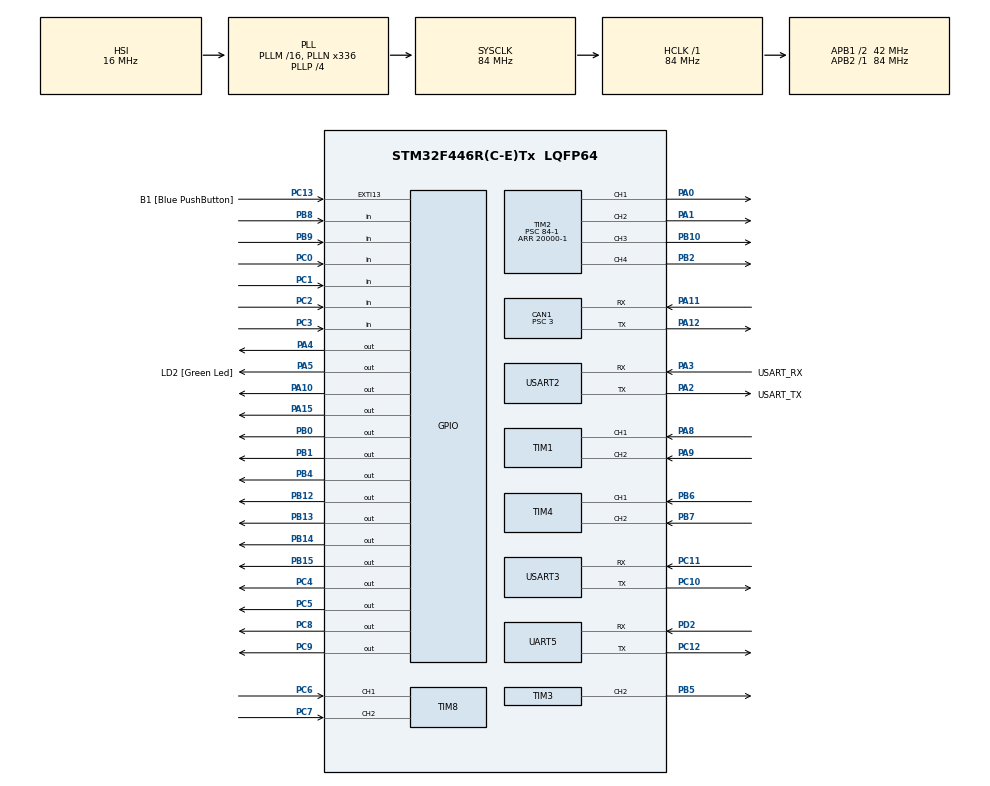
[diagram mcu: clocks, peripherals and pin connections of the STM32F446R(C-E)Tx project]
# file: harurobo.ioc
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CAN1.BS1=CAN_BS1_12TQ
CAN1.CalculateBaudRate=1000000
CAN1.CalculateTimeBit=1000
CAN1.CalculateTimeQuantum=71.42857142857143
CAN1.NART=DISABLE
CAN1.Prescaler=3
CAN1.SJW=CAN_SJW_1TQ
Dma.Request0=TIM3_CH2
Dma.TIM3_CH2.0.Direction=DMA_MEMORY_TO_PERIPH
Dma.TIM3_CH2.0.FIFOMode=DMA_FIFOMODE_DISABLE
Dma.TIM3_CH2.0.Instance=DMA1_Stream5
Dma.TIM3_CH2.0.MemDataAlignment=DMA_MDATAALIGN_WORD
Dma.TIM3_CH2.0.MemInc=DMA_MINC_ENABLE
Dma.TIM3_CH2.0.Mode=DMA_CIRCULAR
Dma.TIM3_CH2.0.PeriphDataAlignment=DMA_PDATAALIGN_WORD
Dma.TIM3_CH2.0.PeriphInc=DMA_PINC_DISABLE
Dma.TIM3_CH2.0.Priority=DMA_PRIORITY_VERY_HIGH
Mcu.Family=STM32F4
Mcu.Name=STM32F446R(C-E)Tx
Mcu.Package=LQFP64
NVIC.CAN1_RX0_IRQn=true\:1\:0\:true\:false\:true\:true\:true\:true
NVIC.DMA1_Stream5_IRQn=true\:0\:0\:false\:false\:true\:false\:true\:true
NVIC.PriorityGroup=NVIC_PRIORITYGROUP_4
NVIC.TIM5_IRQn=true\:3\:0\:true\:false\:true\:true\:true\:true
NVIC.TIM6_DAC_IRQn=true\:2\:0\:true\:false\:true\:true\:true\:true
NVIC.TIM7_IRQn=true\:2\:0\:true\:false\:true\:true\:true\:true
NVIC.UART5_IRQn=true\:1\:0\:true\:false\:true\:true\:true\:true
NVIC.USART2_IRQn=true\:1\:0\:true\:false\:true\:true\:true\:true
NVIC.USART3_IRQn=true\:1\:0\:true\:false\:true\:true\:true\:true
PA0-WKUP.Signal=S_TIM2_CH1_ETR
PA1.Signal=S_TIM2_CH2
PA10.Signal=GPIO_Output
PA11.Mode=CAN_Activate
PA11.Signal=CAN1_RX
PA12.Mode=CAN_Activate
PA12.Signal=CAN1_TX
PA13.GPIO_Label=TMS
PA13.Mode=Serial_Wire
PA13.Signal=SYS_JTMS-SWDIO
PA14.GPIO_Label=TCK
PA14.Mode=Serial_Wire
PA14.Signal=SYS_JTCK-SWCLK
PA15.Signal=GPIO_Output
PA2.GPIO_Label=USART_TX
PA2.Mode=Asynchronous
PA2.Signal=USART2_TX
PA3.GPIO_Label=USART_RX
PA3.Mode=Asynchronous
PA3.Signal=USART2_RX
PA4.Signal=GPIO_Output
PA5.GPIO_Label=LD2 [Green Led]
PA5.Signal=GPIO_Output
PA6.Signal=S_TIM3_CH1
PA8.Signal=S_TIM1_CH1
PA9.Signal=S_TIM1_CH2
PB0.Signal=GPIO_Output
PB1.Signal=GPIO_Output
PB10.Signal=S_TIM2_CH3
PB12.Signal=GPIO_Output
PB13.Signal=GPIO_Output
PB14.Signal=GPIO_Output
PB15.Signal=GPIO_Output
PB2.Signal=S_TIM2_CH4
PB3.GPIO_Label=SWO
PB3.Signal=SYS_JTDO-SWO
PB4.Signal=GPIO_Output
PB5.Signal=S_TIM3_CH2
PB6.Signal=S_TIM4_CH1
PB7.Signal=S_TIM4_CH2
PB8.Signal=GPIO_Input
PB9.Signal=GPIO_Input
PC0.Signal=GPIO_Input
PC1.Signal=GPIO_Input
PC10.Mode=Asynchronous
PC10.Signal=USART3_TX
PC11.Mode=Asynchronous
PC11.Signal=USART3_RX
PC12.Mode=Asynchronous
PC12.Signal=UART5_TX
PC13.GPIO_Label=B1 [Blue PushButton]
PC13.GPIO_ModeDefaultEXTI=GPIO_MODE_IT_FALLING
PC13.Signal=GPXTI13
PC14-OSC32_IN.Mode=LSE-External-Oscillator
PC14-OSC32_IN.Signal=RCC_OSC32_IN
PC15-OSC32_OUT.Mode=LSE-External-Oscillator
PC15-OSC32_OUT.Signal=RCC_OSC32_OUT
PC2.Signal=GPIO_Input
PC3.Signal=GPIO_Input
PC4.Signal=GPIO_Output
PC5.Signal=GPIO_Output
PC6.Signal=S_TIM8_CH1
PC7.Signal=S_TIM8_CH2
PC8.Signal=GPIO_Output
PC9.Signal=GPIO_Output
PD2.Mode=Asynchronous
PD2.Signal=UART5_RX
PH0-OSC_IN.Mode=HSE-External-Oscillator
PH0-OSC_IN.Signal=RCC_OSC_IN
PH1-OSC_OUT.Mode=HSE-External-Oscillator
PH1-OSC_OUT.Signal=RCC_OSC_OUT
ProjectManager.HeapSize=0x200
ProjectManager.StackSize=0x400
ProjectManager.TargetToolchain=CMake
RCC.48MHZClocksFreq_Value=84000000
RCC.AHBFreq_Value=84000000
RCC.APB1CLKDivider=RCC_HCLK_DIV2
RCC.APB1Freq_Value=42000000
RCC.APB1TimFreq_Value=84000000
RCC.APB2Freq_Value=84000000
RCC.APB2TimFreq_Value=84000000
RCC.CortexFreq_Value=84000000
RCC.FLatency-AdvancedSettings=FLASH_LATENCY_2
RCC.HCLKFreq_Value=84000000
RCC.HSE_VALUE=8000000
RCC.HSI_VALUE=16000000
RCC.PLLN=336
RCC.PLLP=RCC_PLLP_DIV4
RCC.SYSCLKFreq_VALUE=84000000
RCC.SYSCLKSource=RCC_SYSCLKSOURCE_PLLCLK
RCC.USBFreq_Value=168000000
RCC.VCOOutputFreq_Value=336000000
SH.S_TIM1_CH1.0=TIM1_CH1,Encoder_Interface
SH.S_TIM1_CH2.0=TIM1_CH2,Encoder_Interface
SH.S_TIM2_CH1_ETR.0=TIM2_CH1,PWM Generation1 CH1
SH.S_TIM2_CH2.0=TIM2_CH2,PWM Generation2 CH2
SH.S_TIM2_CH3.0=TIM2_CH3,PWM Generation3 CH3
SH.S_TIM2_CH4.0=TIM2_CH4,PWM Generation4 CH4
SH.S_TIM3_CH1.0=TIM3_CH1
SH.S_TIM3_CH2.0=TIM3_CH2,PWM Generation2 CH2
SH.S_TIM4_CH1.0=TIM4_CH1,Encoder_Interface
SH.S_TIM4_CH2.0=TIM4_CH2,Encoder_Interface
SH.S_TIM8_CH1.0=TIM8_CH1,Encoder_Interface
SH.S_TIM8_CH2.0=TIM8_CH2,Encoder_Interface
TIM2.Channel-PWM\ Generation1\ CH1=TIM_CHANNEL_1
TIM2.Channel-PWM\ Generation2\ CH2=TIM_CHANNEL_2
TIM2.Channel-PWM\ Generation3\ CH3=TIM_CHANNEL_3
TIM2.Channel-PWM\ Generation4\ CH4=TIM_CHANNEL_4
TIM2.Period=20000-1
TIM2.Prescaler=84-1
TIM3.Channel-PWM\ Generation2\ CH2=TIM_CHANNEL_2
TIM3.Period=15-1
TIM3.Prescaler=7-1
TIM5.Period=8400-1
TIM5.Prescaler=500-1
TIM6.Period=8400-1
TIM6.Prescaler=100-1
TIM7.Period=8400-1
TIM7.Prescaler=10-1
UART5.VirtualMode=Asynchronous
USART2.VirtualMode=VM_ASYNC
USART3.VirtualMode=VM_ASYNC
VP_TIM12_VS_ClockSourceINT.Mode=Internal
VP_TIM13_VS_ClockSourceINT.Mode=Enable_Timer
VP_TIM3_VS_ClockSourceINT.Mode=Internal
VP_TIM5_VS_ClockSourceINT.Mode=Internal
VP_TIM6_VS_ClockSourceINT.Mode=Enable_Timer
VP_TIM7_VS_ClockSourceINT.Mode=Enable_Timer
board=NUCLEO-F446RE

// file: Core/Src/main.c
/* USER CODE BEGIN Header */
/**
  ******************************************************************************
  * @file           : main.c
  * @brief          : Main program body
  ******************************************************************************
  * @attention
  *
  * Copyright (c) 2024 STMicroelectronics.
  * All rights reserved.
  *
  * This software is licensed under terms that can be found in the LICENSE file
  * in the root directory of this software component.
  * If no LICENSE file comes with this software, it is provided AS-IS.
  *
  ******************************************************************************
  */
/* USER CODE END Header */
#include "main.h"
#include "can.h"
#include "dma.h"
#include "tim.h"
#include "usart.h"
#include "gpio.h"

/* USER CODE BEGIN Includes */
#include "main.hpp"
/* USER CODE END Includes */

void SystemClock_Config(void);

int main(void)
{

  /* MCU Configuration--------------------------------------------------------*/

  /* Reset of all peripherals, Initializes the Flash interface and the Systick. */
  HAL_Init();

  /* Configure the system clock */
  SystemClock_Config();

  /* Initialize all configured peripherals */
  MX_GPIO_Init();
  MX_DMA_Init();
  MX_USART2_UART_Init();
  MX_TIM1_Init();
  MX_TIM2_Init();
  MX_TIM3_Init();
  MX_TIM4_Init();
  MX_TIM6_Init();
  MX_TIM7_Init();
  MX_TIM8_Init();
  MX_TIM12_Init();
  MX_TIM13_Init();
  MX_USART3_UART_Init();
  MX_CAN1_Init();
  MX_UART5_Init();
  MX_TIM5_Init();
  /* USER CODE BEGIN 2 */
  setup();
  /* USER CODE END 2 */

  /* Infinite loop */
  /* USER CODE BEGIN WHILE */
  while (1)
  {
    loop();
    /* USER CODE END WHILE */

  }
}

void SystemClock_Config(void)
{
  RCC_OscInitTypeDef RCC_OscInitStruct = {0};
  RCC_ClkInitTypeDef RCC_ClkInitStruct = {0};

  /** Configure the main internal regulator output voltage
  */
  __HAL_RCC_PWR_CLK_ENABLE();
  __HAL_PWR_VOLTAGESCALING_CONFIG(PWR_REGULATOR_VOLTAGE_SCALE3);

  /** Initializes the RCC Oscillators according to the specified parameters
  * in the RCC_OscInitTypeDef structure.
  */
  RCC_OscInitStruct.OscillatorType = RCC_OSCILLATORTYPE_HSI;
  RCC_OscInitStruct.HSIState = RCC_HSI_ON;
  RCC_OscInitStruct.HSICalibrationValue = RCC_HSICALIBRATION_DEFAULT;
  RCC_OscInitStruct.PLL.PLLState = RCC_PLL_ON;
  RCC_OscInitStruct.PLL.PLLSource = RCC_PLLSOURCE_HSI;
  RCC_OscInitStruct.PLL.PLLM = 16;
  RCC_OscInitStruct.PLL.PLLN = 336;
  RCC_OscInitStruct.PLL.PLLP = RCC_PLLP_DIV4;
  RCC_OscInitStruct.PLL.PLLQ = 2;
  RCC_OscInitStruct.PLL.PLLR = 2;
  if (HAL_RCC_OscConfig(&RCC_OscInitStruct) != HAL_OK)
  {
    Error_Handler();
  }

  /** Initializes the CPU, AHB and APB buses clocks
  */
  RCC_ClkInitStruct.ClockType = RCC_CLOCKTYPE_HCLK|RCC_CLOCKTYPE_SYSCLK
                              |RCC_CLOCKTYPE_PCLK1|RCC_CLOCKTYPE_PCLK2;
  RCC_ClkInitStruct.SYSCLKSource = RCC_SYSCLKSOURCE_PLLCLK;
  RCC_ClkInitStruct.AHBCLKDivider = RCC_SYSCLK_DIV1;
  RCC_ClkInitStruct.APB1CLKDivider = RCC_HCLK_DIV2;
  RCC_ClkInitStruct.APB2CLKDivider = RCC_HCLK_DIV1;

  if (HAL_RCC_ClockConfig(&RCC_ClkInitStruct, FLASH_LATENCY_2) != HAL_OK)
  {
    Error_Handler();
  }
}

/* USER CODE BEGIN 4 */
int _write(int file, char *ptr, int len)
{
  HAL_UART_Transmit(&huart2,(uint8_t *)ptr,len,10);
  return len;
}
/* USER CODE END 4 */

void Error_Handler(void)
{
  __disable_irq();
  while (1)
  {
  }
}
